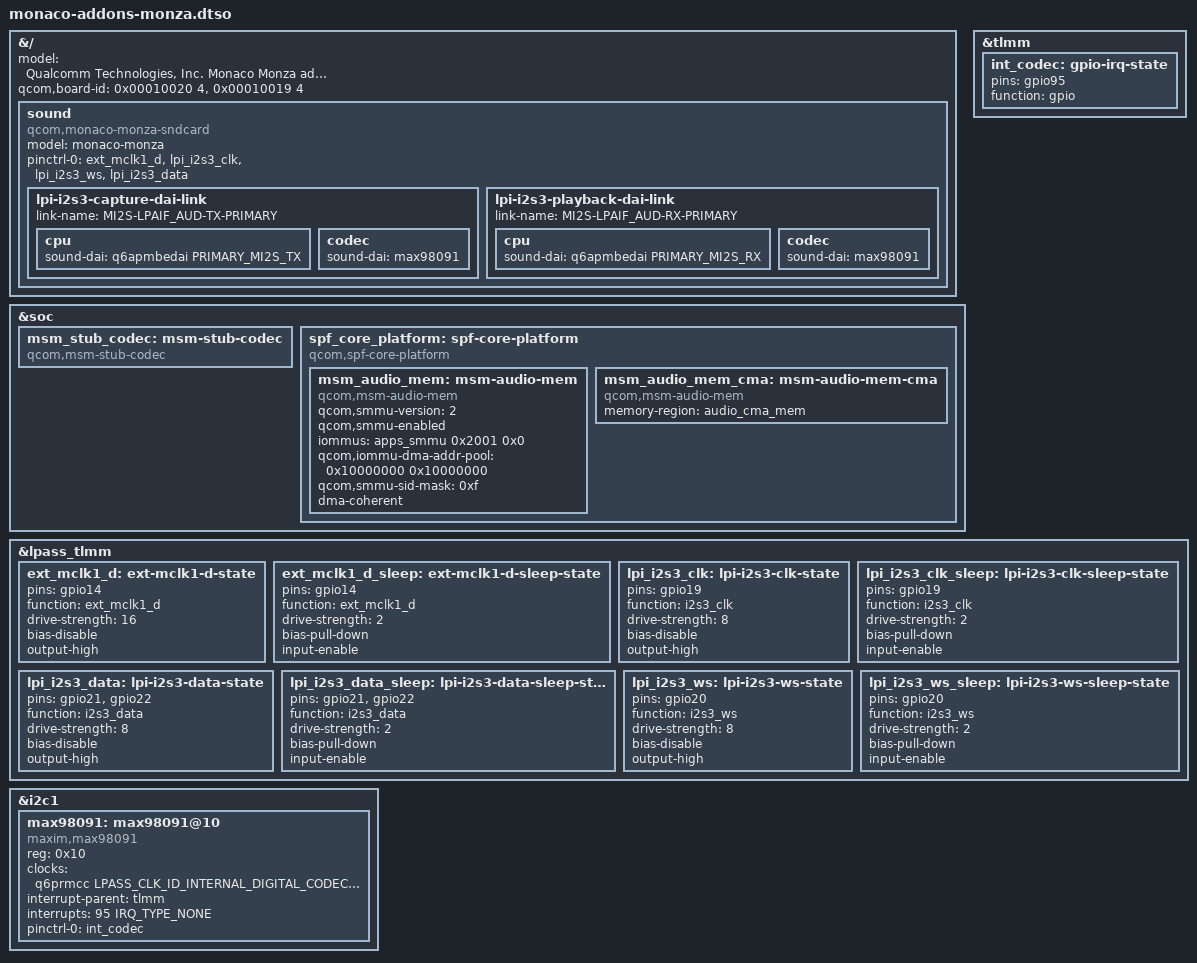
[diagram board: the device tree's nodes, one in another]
// SPDX-License-Identifier: BSD-3-Clause
/*
 * Copyright (c) Qualcomm Technologies, Inc. and/or its subsidiaries.
 */

/dts-v1/;
/plugin/;

#include "qcs8300-addons.dtsi"
#include "qcs8275-thermal-addons.dtsi"

&{/} {
	model = "Qualcomm Technologies, Inc. Monaco Monza addons";
	qcom,board-id = <0x00010020 4>, <0x00010019 4>;
	sound {
		compatible = "qcom,monaco-monza-sndcard";
		model = "monaco-monza";
		pinctrl-names = "default";
		pinctrl-0 = <&ext_mclk1_d>,<&lpi_i2s3_clk>,<&lpi_i2s3_ws>,<&lpi_i2s3_data>;

		lpi-i2s3-capture-dai-link {
			link-name = "MI2S-LPAIF_AUD-TX-PRIMARY";

			cpu {
				sound-dai = <&q6apmbedai PRIMARY_MI2S_TX>;
			};

			codec {
				sound-dai = <&max98091>;
			};
		};

		lpi-i2s3-playback-dai-link {
			link-name = "MI2S-LPAIF_AUD-RX-PRIMARY";

			cpu {
				sound-dai = <&q6apmbedai PRIMARY_MI2S_RX>;
			};

			codec {
				sound-dai = <&max98091>;
			};
		};
	};
};

&soc {

	msm_stub_codec: msm-stub-codec {
		compatible = "qcom,msm-stub-codec";
		#sound-dai-cells = <1>;
	};

	spf_core_platform: spf-core-platform {
		compatible = "qcom,spf-core-platform";

		msm_audio_mem: msm-audio-mem {
			compatible = "qcom,msm-audio-mem";
			qcom,smmu-version = <2>;
			qcom,smmu-enabled;
			iommus = <&apps_smmu 0x2001 0x0>;
			qcom,iommu-dma-addr-pool = <0x10000000 0x10000000>;
			qcom,smmu-sid-mask = /bits/ 64 <0xf>;
			dma-coherent;
		};

		msm_audio_mem_cma: msm-audio-mem-cma {
			compatible = "qcom,msm-audio-mem";
			memory-region = <&audio_cma_mem>;
		};
	};
};

&tlmm {
	int_codec: gpio-irq-state {
		pins = "gpio95";
		function = "gpio";
	};
};

&lpass_tlmm {
	ext_mclk1_d: ext-mclk1-d-state {
		pins = "gpio14";
		function = "ext_mclk1_d";
		drive-strength = <16>;
		bias-disable;
		output-high;
	};

	ext_mclk1_d_sleep: ext-mclk1-d-sleep-state {
		pins = "gpio14";
		function = "ext_mclk1_d";
		drive-strength = <2>;
		bias-pull-down;
		input-enable;
	};

	lpi_i2s3_clk: lpi-i2s3-clk-state {
		pins = "gpio19";
		function = "i2s3_clk";
		drive-strength = <8>;
		bias-disable;
		output-high;
	};

	lpi_i2s3_clk_sleep: lpi-i2s3-clk-sleep-state {
		pins = "gpio19";
		function = "i2s3_clk";
		drive-strength = <2>;
		bias-pull-down;
		input-enable;
	};

	lpi_i2s3_data: lpi-i2s3-data-state {
		pins = "gpio21", "gpio22";
		function = "i2s3_data";
		drive-strength = <8>;
		bias-disable;
		output-high;
	};

	lpi_i2s3_data_sleep: lpi-i2s3-data-sleep-state {
		pins = "gpio21", "gpio22";
		function = "i2s3_data";
		drive-strength = <2>;
		bias-pull-down;
		input-enable;
	};

	lpi_i2s3_ws: lpi-i2s3-ws-state {
		pins = "gpio20";
		function = "i2s3_ws";
		drive-strength = <8>;
		bias-disable;
		output-high;
	};

	lpi_i2s3_ws_sleep: lpi-i2s3-ws-sleep-state {
		pins = "gpio20";
		function = "i2s3_ws";
		drive-strength = <2>;
		bias-pull-down;
		input-enable;
	};
};

&i2c1 {
	status = "okay";
	max98091: max98091@10 {
		compatible = "maxim,max98091";
		reg = <0x10>;
		#sound-dai-cells = <0>;
		clock-names = "mclk";
		clocks = <&q6prmcc LPASS_CLK_ID_INTERNAL_DIGITAL_CODEC_CORE LPASS_CLK_ATTRIBUTE_COUPLE_NO>;
		interrupt-parent = <&tlmm>;
		interrupts = <95 IRQ_TYPE_NONE>;
		pinctrl-names = "default";
		pinctrl-0 = <&int_codec>;
	};
};
